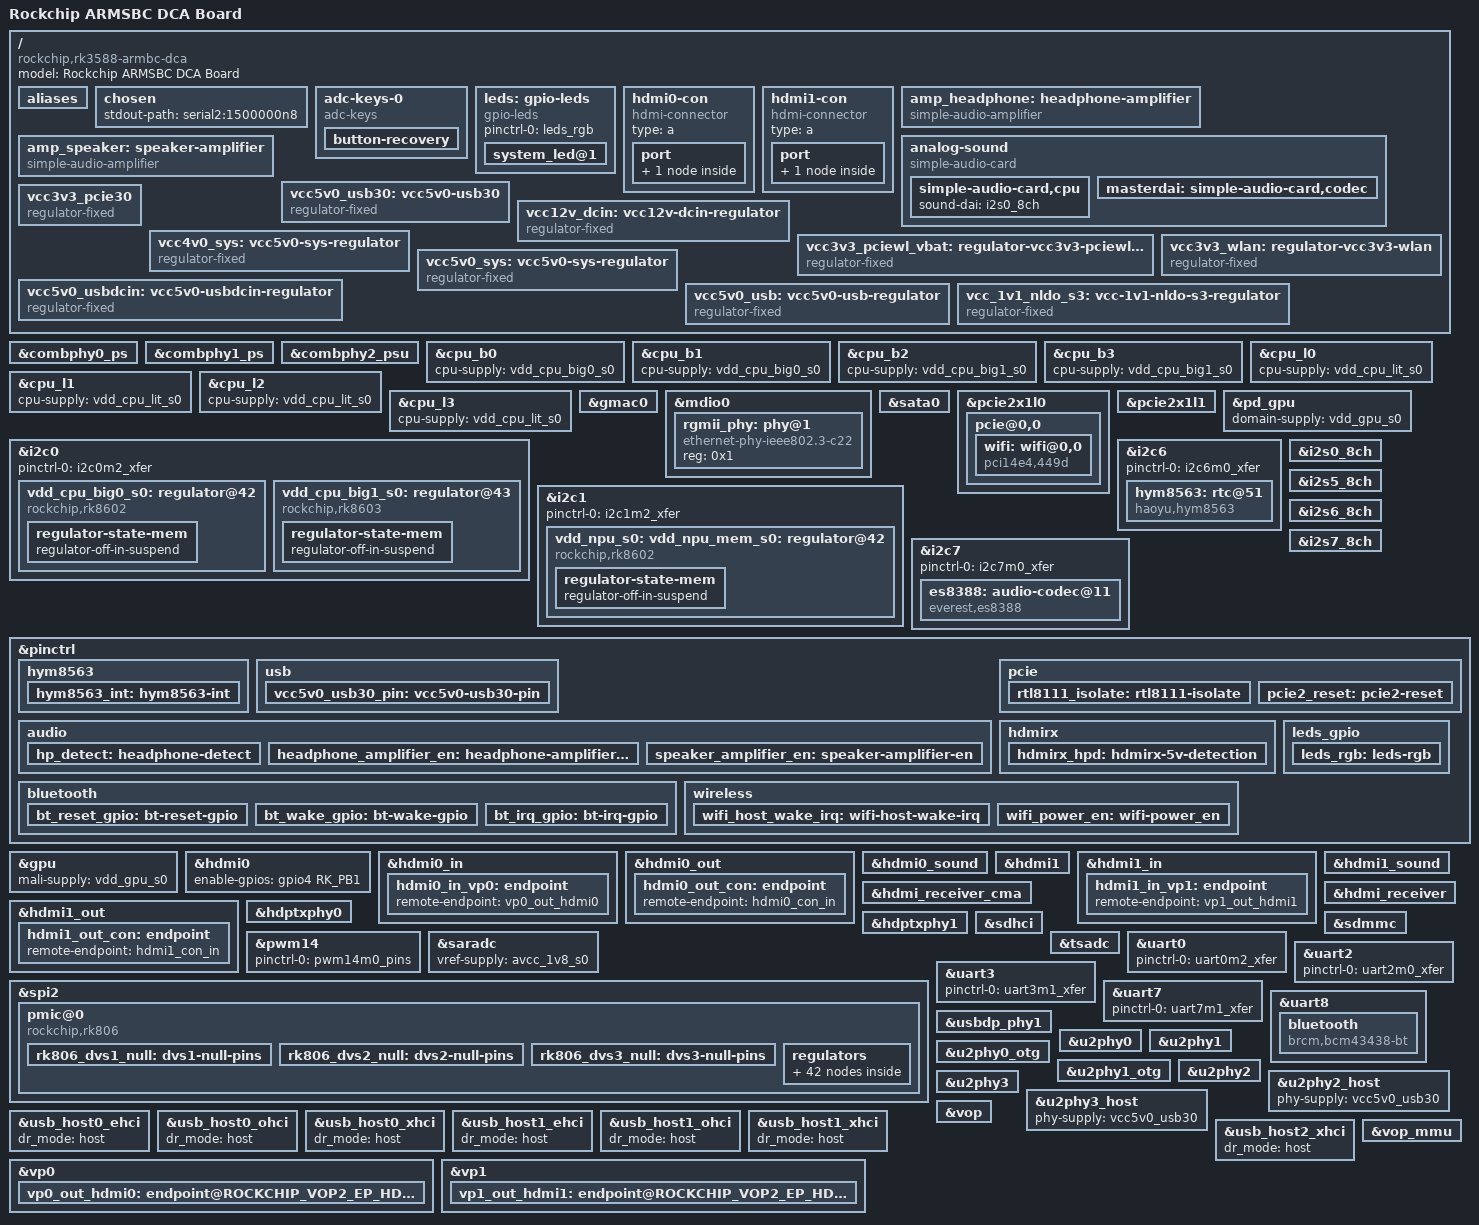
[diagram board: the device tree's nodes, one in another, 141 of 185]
// SPDX-License-Identifier: (GPL-2.0+ OR MIT)
/*
 * Copyright (c) 2024 Rockchip Electronics Co., Ltd.
 *
 */

/dts-v1/;

#include <dt-bindings/gpio/gpio.h>
#include <dt-bindings/input/input.h>
#include <dt-bindings/pinctrl/rockchip.h>
#include <dt-bindings/soc/rockchip,vop2.h>
#include "rk3588.dtsi"

/ {
	model = "Rockchip ARMSBC DCA Board";
	compatible = "rockchip,rk3588-armbc-dca", "rockchip,rk3588";

	aliases {
		mmc0 = &sdhci;
		mmc1 = &sdmmc;
		ethernet0 = &gmac0;
	};

	chosen {
		stdout-path = "serial2:1500000n8";
	};
	
	adc-keys-0 {
		compatible = "adc-keys";
		io-channels = <&saradc 1>;
		io-channel-names = "buttons";
		keyup-threshold-microvolt = <1800000>;
		poll-interval = <100>;

		button-recovery {
			label = "Recovery";
			linux,code = <KEY_VENDOR>;
			press-threshold-microvolt = <2000>;
		};
	};
	
	leds: gpio-leds {
		compatible = "gpio-leds";
		pinctrl-names = "default";
		pinctrl-0 =<&leds_rgb>;
		status = "okay";
 
		system_led@1 {
			gpios = <&gpio4 RK_PB0 GPIO_ACTIVE_HIGH>;
			label = "system_led";
			linux,default-trigger = "heartbeat";
			linux,default-trigger-delay-ms = <0>;
		};
 
	};
	
	hdmi0-con {
		compatible = "hdmi-connector";
		type = "a";

		port {
			hdmi0_con_in: endpoint {
				remote-endpoint = <&hdmi0_out_con>;
			};
		};
	};

	hdmi1-con {
		compatible = "hdmi-connector";
		type = "a";

		port {
			hdmi1_con_in: endpoint {
				remote-endpoint = <&hdmi1_out_con>;
			};
		};
	};

	
	amp_headphone: headphone-amplifier {
		compatible = "simple-audio-amplifier";
		enable-gpios = <&gpio1 RK_PD2 GPIO_ACTIVE_HIGH>;
		pinctrl-names = "default";
		pinctrl-0 = <&headphone_amplifier_en>;
		sound-name-prefix = "Headphones Amplifier";
	};

	amp_speaker: speaker-amplifier {
		compatible = "simple-audio-amplifier";
		enable-gpios = <&gpio1 RK_PD3 GPIO_ACTIVE_HIGH>;
		pinctrl-names = "default";
		pinctrl-0 = <&speaker_amplifier_en>;
		sound-name-prefix = "Speaker Amplifier";
	};
	
	analog-sound {
		compatible = "simple-audio-card";
		pinctrl-names = "default";
		pinctrl-0 = <&hp_detect>;
		simple-audio-card,name = "RK3588 DCA Audio";
		simple-audio-card,aux-devs = <&amp_headphone>, <&amp_speaker>;
		simple-audio-card,bitclock-master = <&masterdai>;
		simple-audio-card,format = "i2s";
		simple-audio-card,frame-master = <&masterdai>;
		simple-audio-card,hp-det-gpios = <&gpio1 RK_PD5 GPIO_ACTIVE_LOW>;
		simple-audio-card,mclk-fs = <256>;
		simple-audio-card,pin-switches = "Headphones", "Speaker";
		simple-audio-card,routing =
			"Speaker Amplifier INL", "LOUT2",
			"Speaker Amplifier INR", "ROUT2",
			"Speaker", "Speaker Amplifier OUTL",
			"Speaker", "Speaker Amplifier OUTR",
			"Headphones Amplifier INL", "LOUT1",
			"Headphones Amplifier INR", "ROUT1",
			"Headphones", "Headphones Amplifier OUTL",
			"Headphones", "Headphones Amplifier OUTR",
			"LINPUT1", "Onboard Microphone",
			"RINPUT1", "Onboard Microphone",
			"LINPUT2", "Microphone Jack",
			"RINPUT2", "Microphone Jack";
		simple-audio-card,widgets =
			"Microphone", "Microphone Jack",
			"Microphone", "Onboard Microphone",
			"Headphone", "Headphones",
			"Speaker", "Speaker";

		simple-audio-card,cpu {
			sound-dai = <&i2s0_8ch>;
		};

		masterdai: simple-audio-card,codec {
			sound-dai = <&es8388>;
			system-clock-frequency = <12288000>;
		};
	};
		
    	vcc5v0_usb30: vcc5v0-usb30 {
        	compatible = "regulator-fixed";
		regulator-name = "vcc5v0-usb30-regulator";
		regulator-boot-on;
        	enable-active-high;
        	pinctrl-names = "default";
		gpio = <&gpio1 RK_PA4 GPIO_ACTIVE_HIGH>;
		pinctrl-0 = <&vcc5v0_usb30_pin>;
        	regulator-min-microvolt = <5000000>;
        	regulator-max-microvolt = <5000000>;
        	vin-supply = <&vcc5v0_sys>;
    	};
    	
	vcc12v_dcin: vcc12v-dcin-regulator {
		compatible = "regulator-fixed";
		regulator-name = "vcc12v_dcin";
		regulator-always-on;
		regulator-boot-on;
		regulator-min-microvolt = <12000000>;
		regulator-max-microvolt = <12000000>;
	};
	
	vcc3v3_pcie30: vcc3v3_pcie30 {
		compatible = "regulator-fixed";
		regulator-name = "vcc3v3_pcie30";
		regulator-always-on;
		regulator-boot-on;
		regulator-min-microvolt = <3000000>;
		regulator-max-microvolt = <3000000>;
		vin-supply = <&vcc12v_dcin>;
	};
	
	vcc4v0_sys: vcc5v0-sys-regulator {
		compatible = "regulator-fixed";
		regulator-name = "vcc4v0_sys";
		regulator-always-on;
		regulator-boot-on;
		regulator-min-microvolt = <4000000>;
		regulator-max-microvolt = <4000000>;
		vin-supply = <&vcc12v_dcin>;
	};
	
	vcc3v3_pciewl_vbat: regulator-vcc3v3-pciewl-vbat {
		compatible = "regulator-fixed";
		regulator-always-on;
		regulator-boot-on;
		regulator-min-microvolt = <3300000>;
		regulator-max-microvolt = <3300000>;
		regulator-name = "wlan-vbat";
		vin-supply = <&vcc_3v3_s0>;
	};
	
	vcc3v3_wlan: regulator-vcc3v3-wlan {
		compatible = "regulator-fixed";
		enable-active-high;
		gpios = <&gpio0 RK_PC4 GPIO_ACTIVE_HIGH>;
		pinctrl-names = "default";
		pinctrl-0 = <&wifi_power_en>;
		regulator-min-microvolt = <3300000>;
		regulator-max-microvolt = <3300000>;
		regulator-name = "wlan-en";
		vin-supply = <&vcc3v3_pciewl_vbat>;
	};
	
	vcc5v0_sys: vcc5v0-sys-regulator {
		compatible = "regulator-fixed";
		regulator-name = "vcc5v0_sys";
		regulator-always-on;
		regulator-boot-on;
		regulator-min-microvolt = <5000000>;
		regulator-max-microvolt = <5000000>;
		vin-supply = <&vcc12v_dcin>;
	};

	vcc5v0_usbdcin: vcc5v0-usbdcin-regulator {
		compatible = "regulator-fixed";
		regulator-name = "vcc5v0_usbdcin";
		regulator-always-on;
		regulator-boot-on;
		regulator-min-microvolt = <5000000>;
		regulator-max-microvolt = <5000000>;
		vin-supply = <&vcc12v_dcin>;
	};

	vcc5v0_usb: vcc5v0-usb-regulator {
		compatible = "regulator-fixed";
		regulator-name = "vcc5v0_usb";
		regulator-always-on;
		pinctrl-names = "default";
		regulator-boot-on;
		regulator-min-microvolt = <5000000>;
		regulator-max-microvolt = <5000000>;
		vin-supply = <&vcc5v0_usbdcin>;
	};

	vcc_1v1_nldo_s3: vcc-1v1-nldo-s3-regulator {
		compatible = "regulator-fixed";
		regulator-name = "vcc_1v1_nldo_s3";
		regulator-always-on;
		regulator-boot-on;
		regulator-min-microvolt = <1100000>;
		regulator-max-microvolt = <1100000>;
		vin-supply = <&vcc5v0_sys>;
	};
};

&combphy0_ps {
	status = "okay";
};

&combphy1_ps {
	status = "okay";
};

&combphy2_psu {
	status = "okay";
};

&cpu_b0 {
	cpu-supply = <&vdd_cpu_big0_s0>;
};

&cpu_b1 {
	cpu-supply = <&vdd_cpu_big0_s0>;
};

&cpu_b2 {
	cpu-supply = <&vdd_cpu_big1_s0>;
};

&cpu_b3 {
	cpu-supply = <&vdd_cpu_big1_s0>;
};

&cpu_l0 {
	cpu-supply = <&vdd_cpu_lit_s0>;
};

&cpu_l1 {
	cpu-supply = <&vdd_cpu_lit_s0>;
};

&cpu_l2 {
	cpu-supply = <&vdd_cpu_lit_s0>;
};

&cpu_l3 {
	cpu-supply = <&vdd_cpu_lit_s0>;
};

&gmac0 {
	phy-mode = "rgmii-rxid";
	clock_in_out = "output";

	snps,reset-gpio = <&gpio4 RK_PB3 GPIO_ACTIVE_LOW>;
	snps,reset-active-low;
	/* Reset time is 20ms, 100ms for rtl8211f */
	snps,reset-delays-us = <0 20000 100000>;

	pinctrl-names = "default";
	pinctrl-0 = <&gmac0_miim
		     &gmac0_tx_bus2
		     &gmac0_rx_bus2
		     &gmac0_rgmii_clk
		     &eth0_pins
		     &gmac0_rgmii_bus>;

	tx_delay = <0x43>;
	rx_delay = <0x3f>; 

	phy-handle = <&rgmii_phy>;
	status = "okay";
};

&mdio0 {
	rgmii_phy: phy@1 {
		compatible = "ethernet-phy-ieee802.3-c22";
		reg = <0x1>;
	};
};

&sata0 {
	status = "okay";
};


&pcie2x1l0 {
        reset-gpios = <&gpio1 RK_PB4 GPIO_ACTIVE_HIGH>;
        pinctrl-names = "default";
        vpcie3v3-supply = <&vcc3v3_wlan>;
        pinctrl-0 = <&pcie2_reset>, <&wifi_host_wake_irq>;
        rockchip,skip-scan-in-resume;
        status = "okay";
        
	pcie@0,0 {
		reg = <0x200000 0 0 0 0>;
		#address-cells = <3>;
		#size-cells = <2>;
		ranges;
		device_type = "pci";
		bus-range = <0x20 0x2f>;

		wifi: wifi@0,0 {
			compatible = "pci14e4,449d";
			reg = <0x210000 0 0 0 0>;
			clocks = <&hym8563>;
			clock-names = "lpo";
		};
	};
};

&pcie2x1l1 {
        reset-gpios = <&gpio4 RK_PA2 GPIO_ACTIVE_HIGH>;
        pinctrl-names = "default";
        pinctrl-0 = <&rtl8111_isolate>;
        status = "okay";
};


&pd_gpu {
	domain-supply = <&vdd_gpu_s0>;
	status = "okay";
};

&i2c0 {
	pinctrl-names = "default";
	pinctrl-0 = <&i2c0m2_xfer>;
	status = "okay";

	vdd_cpu_big0_s0: regulator@42 {
		compatible = "rockchip,rk8602";
		reg = <0x42>;
		fcs,suspend-voltage-selector = <1>;
		regulator-name = "vdd_cpu_big0_s0";
		regulator-always-on;
		regulator-boot-on;
		regulator-min-microvolt = <550000>;
		regulator-max-microvolt = <1050000>;
		regulator-ramp-delay = <2300>;
		vin-supply = <&vcc4v0_sys>;

		regulator-state-mem {
			regulator-off-in-suspend;
		};
	};

	vdd_cpu_big1_s0: regulator@43 {
		compatible = "rockchip,rk8603", "rockchip,rk8602";
		reg = <0x43>;
		fcs,suspend-voltage-selector = <1>;
		regulator-name = "vdd_cpu_big1_s0";
		regulator-always-on;
		regulator-boot-on;
		regulator-min-microvolt = <550000>;
		regulator-max-microvolt = <1050000>;
		regulator-ramp-delay = <2300>;
		vin-supply = <&vcc4v0_sys>;

		regulator-state-mem {
			regulator-off-in-suspend;
		};
	};
};

&i2c1 {
	pinctrl-names = "default";
	pinctrl-0 = <&i2c1m2_xfer>;
	status = "okay";

	vdd_npu_s0: vdd_npu_mem_s0: regulator@42 {
		compatible = "rockchip,rk8602";
		reg = <0x42>;
		fcs,suspend-voltage-selector = <1>;
		regulator-always-on;
		regulator-boot-on;
		regulator-min-microvolt = <550000>;
		regulator-max-microvolt = <950000>;
		regulator-name = "vdd_npu_s0";
		regulator-ramp-delay = <2300>;
		vin-supply = <&vcc4v0_sys>;

		regulator-state-mem {
			regulator-off-in-suspend;
		};
	};
};

&i2c6 {
	status = "okay";
	pinctrl-0 = <&i2c6m0_xfer>;

	hym8563: rtc@51 {
		compatible = "haoyu,hym8563";
		reg = <0x51>;
		#clock-cells = <0>;
		clock-output-names = "hym8563";
		interrupt-parent = <&gpio0>;
		interrupts = <RK_PB0 IRQ_TYPE_LEVEL_LOW>;
		pinctrl-names = "default";
		pinctrl-0 = <&hym8563_int>;
		wakeup-source;
	};
};

&i2c7 {
	status = "okay";
	pinctrl-0 = <&i2c7m0_xfer>;

	es8388: audio-codec@11 {
		compatible = "everest,es8388", "everest,es8328";
		reg = <0x11>;
		clocks = <&cru I2S0_8CH_MCLKOUT>;
		assigned-clocks = <&cru I2S0_8CH_MCLKOUT>;
		assigned-clock-rates = <12288000>;
		AVDD-supply = <&avcc_1v8_s0>;
		DVDD-supply = <&avcc_1v8_s0>;
		HPVDD-supply = <&vcc_3v3_s0>;
		PVDD-supply = <&vcc_3v3_s0>;
		#sound-dai-cells = <0>;
	};
};

&i2s0_8ch {
	pinctrl-0 = <&i2s0_lrck
		     &i2s0_mclk
		     &i2s0_sclk
		     &i2s0_sdi0
		     &i2s0_sdo0>;
	status = "okay";
};

&i2s5_8ch {
	status = "okay";
};

&i2s6_8ch {
	status = "okay";
};

&i2s7_8ch {
	status = "okay";
};
	
&pinctrl {

	hym8563 {
		hym8563_int: hym8563-int {
			rockchip,pins = <0 RK_PB0 RK_FUNC_GPIO &pcfg_pull_up>;
		};
	};

	usb {
		
		vcc5v0_usb30_pin: vcc5v0-usb30-pin {
			rockchip,pins = <1 RK_PA4 RK_FUNC_GPIO &pcfg_pull_none>;
		};
	};
	
	audio {
		hp_detect: headphone-detect {
			rockchip,pins = <1 RK_PD5 RK_FUNC_GPIO &pcfg_pull_none>;
		};

		headphone_amplifier_en: headphone-amplifier-en {
			rockchip,pins = <1 RK_PD2 RK_FUNC_GPIO &pcfg_pull_none>;
		};

		speaker_amplifier_en: speaker-amplifier-en {
			rockchip,pins = <1 RK_PD3 RK_FUNC_GPIO &pcfg_pull_none>;
		};
	};

	pcie {
                rtl8111_isolate: rtl8111-isolate {
                        rockchip,pins = <4 RK_PB6 RK_FUNC_GPIO &pcfg_pull_up>;
                };
                
         	pcie2_reset: pcie2-reset {
			rockchip,pins = <1 RK_PB4 RK_FUNC_GPIO &pcfg_pull_up>;
		};
        };
                
        bluetooth {

		bt_reset_gpio: bt-reset-gpio {
			rockchip,pins = <0 RK_PC6 RK_FUNC_GPIO &pcfg_pull_none>;
		};

		bt_wake_gpio: bt-wake-gpio {
			rockchip,pins = <0 RK_PC5 RK_FUNC_GPIO &pcfg_pull_none>;
		};

		bt_irq_gpio: bt-irq-gpio {
			rockchip,pins = <0 RK_PA0 RK_FUNC_GPIO &pcfg_pull_none>;
		};
	};
	
	hdmirx {
		hdmirx_hpd: hdmirx-5v-detection {
			rockchip,pins = <2 RK_PB5 RK_FUNC_GPIO &pcfg_pull_none>;
		};
	};

	wireless {
		wifi_host_wake_irq: wifi-host-wake-irq {
			rockchip,pins = <0 RK_PB2 RK_FUNC_GPIO &pcfg_pull_down>;
		};
	
		wifi_power_en: wifi-power_en {
			rockchip,pins = <0 RK_PC4 RK_FUNC_GPIO &pcfg_pull_up>;
    		};
    	};
    	
    	leds_gpio {
        	leds_rgb: leds-rgb {
                	rockchip,pins = <4 RK_PB0 RK_FUNC_GPIO &pcfg_pull_up>;
        	};
    	};
};


&gpu {
	mali-supply = <&vdd_gpu_s0>;
	status = "okay";
};

&hdmi0 {
	status = "okay";
	enable-gpios = <&gpio4 RK_PB1 GPIO_ACTIVE_HIGH>;
};

&hdmi0_in {
	hdmi0_in_vp0: endpoint {
		remote-endpoint = <&vp0_out_hdmi0>;
	};
};

&hdmi0_out {
	hdmi0_out_con: endpoint {
		remote-endpoint = <&hdmi0_con_in>;
	};
};

&hdmi0_sound {
	status = "okay";	
};

&hdmi1 {
	status = "okay";
	//enable-gpios = <&gpio4 RK_PB2 GPIO_ACTIVE_HIGH>;
};

&hdmi1_in {
	hdmi1_in_vp1: endpoint {
		remote-endpoint = <&vp1_out_hdmi1>;
	};
};

&hdmi1_out {
	hdmi1_out_con: endpoint {
		remote-endpoint = <&hdmi1_con_in>;
	};
};

&hdmi1_sound {
	status = "okay";
};

&hdmi_receiver_cma {
	status = "okay";
};

&hdmi_receiver {
	hpd-gpios = <&gpio2 RK_PB5 GPIO_ACTIVE_LOW>;
	pinctrl-0 = <&hdmim1_rx_cec &hdmim1_rx_hpdin &hdmim1_rx_scl &hdmim1_rx_sda &hdmirx_hpd>;
	pinctrl-names = "default";
	status = "okay";
};

&hdptxphy0 {
	status = "okay";
};

&hdptxphy1 {
	status = "okay";
};

&pwm14 {
	status = "okay";
	pinctrl-0 = <&pwm14m0_pins>;
};

&saradc {
	vref-supply = <&avcc_1v8_s0>;
	status = "okay";
};

&sdhci {
	bus-width = <8>;
	mmc-hs400-1_8v;
	mmc-hs400-enhanced-strobe;
	no-sdio;
	no-sd;
	non-removable;
	status = "okay";
};

&sdmmc {
	bus-width = <4>;
	cap-mmc-highspeed;
	cap-sd-highspeed;
	disable-wp;
	max-frequency = <200000000>;
	no-sdio;
	no-mmc;
	sd-uhs-sdr104;
	vmmc-supply = <&vcc_3v3_s3>;
	vqmmc-supply = <&vccio_sd_s0>;
	status = "okay";
};

&spi2 {
	status = "okay";
	assigned-clocks = <&cru CLK_SPI2>;
	assigned-clock-rates = <200000000>;
	pinctrl-names = "default";
	pinctrl-0 = <&spi2m2_cs0 &spi2m2_pins>;
	num-cs = <1>;

	pmic@0 {
		compatible = "rockchip,rk806";
		spi-max-frequency = <1000000>;
		reg = <0x0>;

		interrupt-parent = <&gpio0>;
		interrupts = <7 IRQ_TYPE_LEVEL_LOW>;

		pinctrl-names = "default";
		pinctrl-0 = <&pmic_pins>, <&rk806_dvs1_null>,
			    <&rk806_dvs2_null>, <&rk806_dvs3_null>;

		system-power-controller;

		vcc1-supply = <&vcc4v0_sys>;
		vcc2-supply = <&vcc4v0_sys>;
		vcc3-supply = <&vcc4v0_sys>;
		vcc4-supply = <&vcc4v0_sys>;
		vcc5-supply = <&vcc4v0_sys>;
		vcc6-supply = <&vcc4v0_sys>;
		vcc7-supply = <&vcc4v0_sys>;
		vcc8-supply = <&vcc4v0_sys>;
		vcc9-supply = <&vcc4v0_sys>;
		vcc10-supply = <&vcc4v0_sys>;
		vcc11-supply = <&vcc_2v0_pldo_s3>;
		vcc12-supply = <&vcc4v0_sys>;
		vcc13-supply = <&vcc_1v1_nldo_s3>;
		vcc14-supply = <&vcc_1v1_nldo_s3>;
		vcca-supply = <&vcc4v0_sys>;

		gpio-controller;
		#gpio-cells = <2>;

		rk806_dvs1_null: dvs1-null-pins {
			pins = "gpio_pwrctrl1";
			function = "pin_fun0";
		};

		rk806_dvs2_null: dvs2-null-pins {
			pins = "gpio_pwrctrl2";
			function = "pin_fun0";
		};

		rk806_dvs3_null: dvs3-null-pins {
			pins = "gpio_pwrctrl3";
			function = "pin_fun0";
		};

		regulators {
			vdd_gpu_s0: vdd_gpu_mem_s0: dcdc-reg1 {
				regulator-boot-on;
				regulator-min-microvolt = <550000>;
				regulator-max-microvolt = <950000>;
				regulator-ramp-delay = <12500>;
				regulator-name = "vdd_gpu_s0";
				regulator-enable-ramp-delay = <400>;

				regulator-state-mem {
					regulator-off-in-suspend;
				};
			};

			vdd_cpu_lit_s0: vdd_cpu_lit_mem_s0: dcdc-reg2 {
				regulator-always-on;
				regulator-boot-on;
				regulator-min-microvolt = <550000>;
				regulator-max-microvolt = <950000>;
				regulator-ramp-delay = <12500>;
				regulator-name = "vdd_cpu_lit_s0";

				regulator-state-mem {
					regulator-off-in-suspend;
				};
			};

			vdd_log_s0: dcdc-reg3 {
				regulator-always-on;
				regulator-boot-on;
				regulator-min-microvolt = <675000>;
				regulator-max-microvolt = <750000>;
				regulator-ramp-delay = <12500>;
				regulator-name = "vdd_log_s0";

				regulator-state-mem {
					regulator-off-in-suspend;
					regulator-suspend-microvolt = <750000>;
				};
			};

			vdd_vdenc_s0: vdd_vdenc_mem_s0: dcdc-reg4 {
				regulator-always-on;
				regulator-boot-on;
				regulator-min-microvolt = <550000>;
				regulator-max-microvolt = <950000>;
				regulator-ramp-delay = <12500>;
				regulator-name = "vdd_vdenc_s0";

				regulator-state-mem {
					regulator-off-in-suspend;
				};
			};

			vdd_ddr_s0: dcdc-reg5 {
				regulator-always-on;
				regulator-boot-on;
				regulator-min-microvolt = <675000>;
				regulator-max-microvolt = <900000>;
				regulator-ramp-delay = <12500>;
				regulator-name = "vdd_ddr_s0";

				regulator-state-mem {
					regulator-off-in-suspend;
					regulator-suspend-microvolt = <850000>;
				};
			};

			vdd2_ddr_s3: dcdc-reg6 {
				regulator-always-on;
				regulator-boot-on;
				regulator-name = "vdd2_ddr_s3";

				regulator-state-mem {
					regulator-on-in-suspend;
				};
			};

			vcc_2v0_pldo_s3: dcdc-reg7 {
				regulator-always-on;
				regulator-boot-on;
				regulator-min-microvolt = <2000000>;
				regulator-max-microvolt = <2000000>;
				regulator-ramp-delay = <12500>;
				regulator-name = "vdd_2v0_pldo_s3";

				regulator-state-mem {
					regulator-on-in-suspend;
					regulator-suspend-microvolt = <2000000>;
				};
			};

			vcc_3v3_s3: dcdc-reg8 {
				regulator-always-on;
				regulator-boot-on;
				regulator-min-microvolt = <3300000>;
				regulator-max-microvolt = <3300000>;
				regulator-name = "vcc_3v3_s3";

				regulator-state-mem {
					regulator-on-in-suspend;
					regulator-suspend-microvolt = <3300000>;
				};
			};

			vddq_ddr_s0: dcdc-reg9 {
				regulator-always-on;
				regulator-boot-on;
				regulator-name = "vddq_ddr_s0";

				regulator-state-mem {
					regulator-off-in-suspend;
				};
			};

			vcc_1v8_s3: dcdc-reg10 {
				regulator-always-on;
				regulator-boot-on;
				regulator-min-microvolt = <1800000>;
				regulator-max-microvolt = <1800000>;
				regulator-name = "vcc_1v8_s3";

				regulator-state-mem {
					regulator-on-in-suspend;
					regulator-suspend-microvolt = <1800000>;
				};
			};

			avcc_1v8_s0: pldo-reg1 {
				regulator-always-on;
				regulator-boot-on;
				regulator-min-microvolt = <1800000>;
				regulator-max-microvolt = <1800000>;
				regulator-name = "avcc_1v8_s0";

				regulator-state-mem {
					regulator-off-in-suspend;
				};
			};

			vcc_1v8_s0: pldo-reg2 {
				regulator-always-on;
				regulator-boot-on;
				regulator-min-microvolt = <1800000>;
				regulator-max-microvolt = <1800000>;
				regulator-name = "vcc_1v8_s0";

				regulator-state-mem {
					regulator-off-in-suspend;
					regulator-suspend-microvolt = <1800000>;
				};
			};

			avdd_1v2_s0: pldo-reg3 {
				regulator-always-on;
				regulator-boot-on;
				regulator-min-microvolt = <1200000>;
				regulator-max-microvolt = <1200000>;
				regulator-name = "avdd_1v2_s0";

				regulator-state-mem {
					regulator-off-in-suspend;
				};
			};

			vcc_3v3_s0: pldo-reg4 {
				regulator-always-on;
				regulator-boot-on;
				regulator-min-microvolt = <3300000>;
				regulator-max-microvolt = <3300000>;
				regulator-ramp-delay = <12500>;
				regulator-name = "vcc_3v3_s0";

				regulator-state-mem {
					regulator-off-in-suspend;
				};
			};

			vccio_sd_s0: pldo-reg5 {
				regulator-always-on;
				regulator-boot-on;
				regulator-min-microvolt = <1800000>;
				regulator-max-microvolt = <3300000>;
				regulator-ramp-delay = <12500>;
				regulator-name = "vccio_sd_s0";

				regulator-state-mem {
					regulator-off-in-suspend;
				};
			};

			pldo6_s3: pldo-reg6 {
				regulator-always-on;
				regulator-boot-on;
				regulator-min-microvolt = <1800000>;
				regulator-max-microvolt = <1800000>;
				regulator-name = "pldo6_s3";

				regulator-state-mem {
					regulator-on-in-suspend;
					regulator-suspend-microvolt = <1800000>;
				};
			};

			vdd_0v75_s3: nldo-reg1 {
				regulator-always-on;
				regulator-boot-on;
				regulator-min-microvolt = <750000>;
				regulator-max-microvolt = <750000>;
				regulator-name = "vdd_0v75_s3";

				regulator-state-mem {
					regulator-on-in-suspend;
					regulator-suspend-microvolt = <750000>;
				};
			};

			vdd_ddr_pll_s0: nldo-reg2 {
				regulator-always-on;
				regulator-boot-on;
				regulator-min-microvolt = <850000>;
				regulator-max-microvolt = <850000>;
				regulator-name = "vdd_ddr_pll_s0";

				regulator-state-mem {
					regulator-off-in-suspend;
					regulator-suspend-microvolt = <850000>;
				};
			};

			avdd_0v75_s0: nldo-reg3 {
				regulator-always-on;
				regulator-boot-on;
				regulator-min-microvolt = <750000>;
				regulator-max-microvolt = <750000>;
				regulator-name = "avdd_0v75_s0";

				regulator-state-mem {
					regulator-off-in-suspend;
				};
			};

			vdd_0v85_s0: nldo-reg4 {
				regulator-always-on;
				regulator-boot-on;
				regulator-min-microvolt = <850000>;
				regulator-max-microvolt = <850000>;
				regulator-name = "vdd_0v85_s0";

				regulator-state-mem {
					regulator-off-in-suspend;
				};
			};

			vdd_0v75_s0: nldo-reg5 {
				regulator-always-on;
				regulator-boot-on;
				regulator-min-microvolt = <750000>;
				regulator-max-microvolt = <750000>;
				regulator-name = "vdd_0v75_s0";

				regulator-state-mem {
					regulator-off-in-suspend;
				};
			};
		};
	};
};

&tsadc {
	status = "okay";
};

&uart0 {
	pinctrl-0 = <&uart0m2_xfer>;
	status = "okay";
};

&uart2 {
	pinctrl-0 = <&uart2m0_xfer>;
	status = "okay";
};

&uart3 {
	pinctrl-0 = <&uart3m1_xfer>;
	status = "okay";
};

&uart7 {
	pinctrl-0 = <&uart7m1_xfer>;
	status = "okay";
};

&uart8 {
	pinctrl-names = "default";
	pinctrl-0 = <&uart8m1_xfer>, <&uart8m1_ctsn>, <&uart8m1_rtsn>;
	uart-has-rtscts;
	status = "okay";

	bluetooth {
		compatible = "brcm,bcm43438-bt";
		clocks = <&hym8563>;
		clock-names = "lpo";

		shutdown-gpios       = <&gpio0 RK_PC6 GPIO_ACTIVE_HIGH>;  // BT_REG_ON_H
		device-wakeup-gpios  = <&gpio0 RK_PA0 GPIO_ACTIVE_HIGH>;  // BT_WAKE
		host-wakeup-gpios    = <&gpio0 RK_PC5 GPIO_ACTIVE_HIGH>;  // HOST_WAKE_BT_H

		vbat-supply = <&vcc_3v3_s0>;
		vddio-supply = <&vcc_1v8_s0>;

		pinctrl-names = "default";
		pinctrl-0 = <&bt_reset_gpio>, <&bt_wake_gpio>, <&bt_irq_gpio>;
	};
};

&usbdp_phy1 {
	status = "okay";
};

&u2phy0 {
	status = "okay";
};

&u2phy1 {
	status = "okay";
};

&u2phy0_otg {
	phy-supply = <&vcc5v0_usb30>;
	dr_mode = "host";
	status = "okay";
};

&u2phy1_otg {
	phy-supply = <&vcc5v0_usb30>;
	dr_mode = "host";
	status = "okay";
};

&u2phy2 {
	status = "okay";
};

&u2phy2_host {
	phy-supply = <&vcc5v0_usb30>;
	status = "okay";
};

&u2phy3 {
	status = "okay";
};

&u2phy3_host {
	phy-supply = <&vcc5v0_usb30>;
	status = "okay";
};

&usb_host0_ehci {
	dr_mode = "host";
	status = "okay";
};

&usb_host0_ohci {
	dr_mode = "host";
	status = "okay";
};

&usb_host0_xhci {
	dr_mode = "host";
	status = "okay";
};

&usb_host1_ehci {
	dr_mode = "host";
	status = "okay";
};

&usb_host1_ohci {
	dr_mode = "host";
	status = "okay";
};

&usb_host1_xhci {
	dr_mode = "host";
	status = "okay";
};

&usb_host2_xhci {
	dr_mode = "host";
	status = "okay";
};

&vop {
	status = "okay";
};

&vop_mmu {
	status = "okay";
};

&vp0 {
	vp0_out_hdmi0: endpoint@ROCKCHIP_VOP2_EP_HDMI0 {
		reg = <ROCKCHIP_VOP2_EP_HDMI0>;
		remote-endpoint = <&hdmi0_in_vp0>;
	};
};

&vp1 {
	vp1_out_hdmi1: endpoint@ROCKCHIP_VOP2_EP_HDMI1 {
		reg = <ROCKCHIP_VOP2_EP_HDMI1>;
		remote-endpoint = <&hdmi1_in_vp1>;
	};
};
